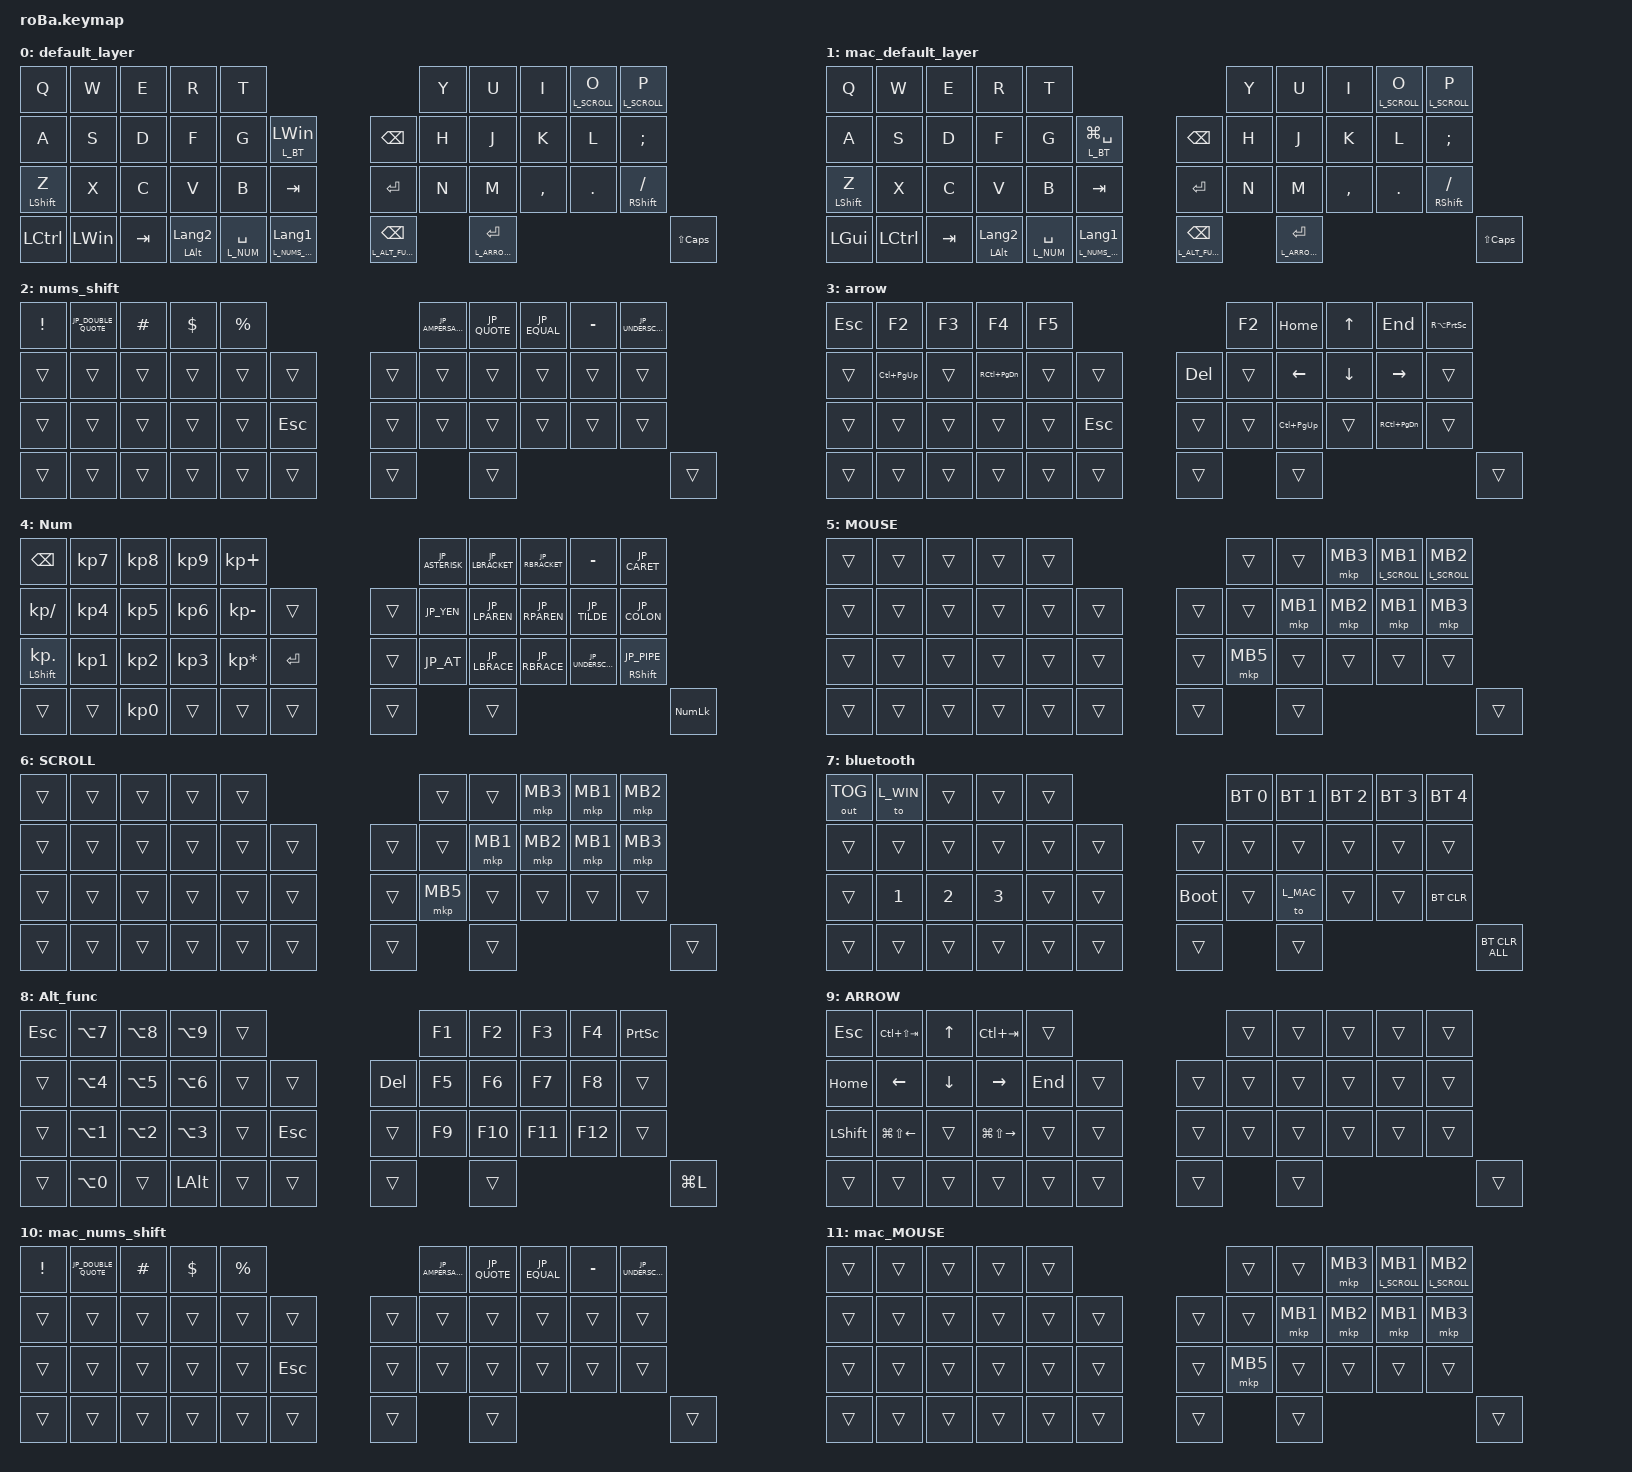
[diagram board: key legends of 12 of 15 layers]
#include <behaviors.dtsi>
#include <dt-bindings/zmk/bt.h>
#include <dt-bindings/zmk/keys.h>
#include <dt-bindings/zmk/outputs.h>
#include <dt-bindings/zmk/pointing.h>

// #include "keys_jp.h"

#define ZMK_POINTING_DEFAULT_SCRL_VAL 80

// #define AML 4  // Your AML layer index / AMLレイヤーのインデックス

// Layer indices / レイヤー番号
// mac_default_layer は共有レイヤー(arrow, Num, bluetooth)より下に置く必要がある
// MAC 版レイヤー(L_MAC_*)は conditional_layers で「MAC + 元レイヤー」のとき自動で有効になる
#define L_WIN             0
#define L_MAC             1
#define L_NUMS_SHIFT      2
#define L_ARROW_FN        3
#define L_NUM             4
#define L_MOUSE           5   // AML: roBa_R.overlay の AML と揃えること
#define L_SCROLL          6
#define L_BT              7
#define L_ALT_FUNC        8
#define L_ARROW           9
#define L_MAC_NUMS_SHIFT 10
#define L_MAC_MOUSE      11
#define L_MAC_SCROLL     12
#define L_MAC_ALT_FUNC   13
#define L_MAC_ARROW      14

#define JP_QUOTE        AMPERSAND         // '  (LS(N7) → JP Shift+7 = ')
#define JP_DOUBLE_QUOTE AT_SIGN           // "  (LS(N2) → JP Shift+2 = ")
#define JP_AMPERSAND    CARET             // &  (LS(N6) → JP Shift+6 = &)
#define JP_EQUAL        UNDERSCORE        // =  (LS(MINUS) → JP Shift+- = =)
#define JP_CARET        EQUAL             // ^
#define JP_YEN          INT3              // ¥  (HID 0x89)
#define JP_PLUS         COLON             // +  (LS(SEMICOLON) → JP Shift+; = +)
#define JP_TILDE        PLUS              // ~  (LS(EQUAL) → JP Shift+^ = ~)
#define JP_PIPE         LS(INT3)          // |  (LS(0x89))
#define JP_AT           LEFT_BRACKET      // @
#define JP_COLON        SINGLE_QUOTE      // :
#define JP_ASTERISK     DOUBLE_QUOTES     // *  (LS(SINGLE_QUOTE) → JP Shift+: = *)
#define JP_BACKQUOTE    LEFT_BRACE        // `  (LS(LEFT_BRACKET) → JP Shift+@ = `)
#define JP_UNDERSCORE   LS(INT1)          // _  (LS(0x87))
#define JP_LBRACKET     RIGHT_BRACKET     // [
#define JP_RBRACKET     BACKSLASH         // ]
#define JP_LPAREN       ASTERISK          // (  (LS(N8) → JP Shift+8 = ()
#define JP_RPAREN       LEFT_PARENTHESIS  // )  (LS(N9) → JP Shift+9 = ))
#define JP_LBRACE       RIGHT_BRACE       // {  (LS(RIGHT_BRACKET) → JP Shift+[ = {)
#define JP_RBRACE       PIPE              // }  (LS(BACKSLASH) → JP Shift+] = })
#define JP_KANA         LANGUAGE_1        // かな
#define JP_EISU         LANGUAGE_2        // 英数
#define JP_HANZEN       GRAVE             // 半角/全角

&mt {
    flavor = "balanced";
    quick-tap-ms = <0>;
};

&trackball {
    scroll-layers = <L_SCROLL>;

    // arrows {
    //     layers = <3>;
    //     bindings =
    //         <&kp RIGHT_ARROW>,
    //         <&kp LEFT_ARROW>,
    //         <&kp UP_ARROW>,
    //         <&kp DOWN_ARROW>;
    //     tick = <10>;
    //     wait-ms = <5>;
    //     tap-ms = <5>;
    // };
};

/ {
    zip_temp_layer_threshold: zip_temp_layer_threshold {
        compatible = "zmk,input-processor-temp-layer-threshold";
        #input-processor-cells = <2>;
        
        // Cumulative movement required before activation
        // AML発動に必要な累積移動量（大きくするほど誤作動しにくい）
        threshold = <25>;

        // Key positions that won't deactivate the layer
        // 以下で指定したキー以外を押すとAML解除
        excluded-positions = <7 8 9 17 18 19 20 21 22 34> ;

        // Don't activate if key was pressed within this time
        // キー入力から300ms間はAMLを発動しない
        require-prior-idle-ms = <300>;

        // Reset accumulated movement after this timeout
        // 蓄積された移動量をリセットするまでの時間（短くするとドリフト蓄積を防ぐ）
        reset-timeout-ms = <100>;
    };


    combos { compatible = "zmk,combos"; };

    macros {
        to_layer_0: to_layer_0 {
            compatible = "zmk,behavior-macro-one-param";
            #binding-cells = <1>;
            bindings = <&to 0 &macro_param_1to1 &kp MACRO_PLACEHOLDER>;
            label = "TO_LAYER_0";
        };

        to_layer_mac: to_layer_mac {
            compatible = "zmk,behavior-macro-one-param";
            #binding-cells = <1>;
            bindings = <&to L_MAC &macro_param_1to1 &kp MACRO_PLACEHOLDER>;
            label = "TO_LAYER_MAC";
        };
    };

    conditional_layers {
        compatible = "zmk,conditional-layers";

        mac_nums_shift {
            if-layers = <L_MAC L_NUMS_SHIFT>;
            then-layer = <L_MAC_NUMS_SHIFT>;
        };

        mac_mouse {
            if-layers = <L_MAC L_MOUSE>;
            then-layer = <L_MAC_MOUSE>;
        };

        mac_scroll {
            if-layers = <L_MAC L_SCROLL>;
            then-layer = <L_MAC_SCROLL>;
        };

        mac_alt_func {
            if-layers = <L_MAC L_ALT_FUNC>;
            then-layer = <L_MAC_ALT_FUNC>;
        };

        mac_arrow {
            if-layers = <L_MAC L_ARROW>;
            then-layer = <L_MAC_ARROW>;
        };
    };

    behaviors {
        lt_to_layer_0: lt_to_layer_0 {
            compatible = "zmk,behavior-hold-tap";
            label = "LAYER_TAP_TO_0";
            bindings = <&mo>, <&to_layer_0>;

            #binding-cells = <2>;
            tapping-term-ms = <200>;
        };

        lt_to_layer_mac: lt_to_layer_mac {
            compatible = "zmk,behavior-hold-tap";
            label = "LAYER_TAP_TO_MAC";
            bindings = <&mo>, <&to_layer_mac>;

            #binding-cells = <2>;
            tapping-term-ms = <200>;
        };

        lt_to_layer_0_delay: lt_to_layer_0_delay {
            compatible = "zmk,behavior-hold-tap";
            label = "LAYER_TAP_TO_0_delay";
            bindings = <&mo>, <&to_layer_0>;
            flavor = "balanced";

            #binding-cells = <2>;
            tapping-term-ms = <900>;
            quick-tap-ms = <900>;
            require-prior-idle-ms = <120>;
            hold-trigger-key-positions = <>;
        };

        lt_kp_delay: lt_kp_delay {
            compatible = "zmk,behavior-hold-tap";
            label = "LAYER_TAP_KP_DELAY";
            bindings = <&mo>, <&kp>;
            flavor = "balanced";

            #binding-cells = <2>;
            tapping-term-ms = <900>;
            quick-tap-ms = <900>;
            require-prior-idle-ms = <120>;
            hold-trigger-key-positions = <>;
        };

        mo_mb1_delay: mo_mb1_delay {
            compatible = "zmk,behavior-hold-tap";
            label = "MO_MB1_DELAY";
            #binding-cells = <2>;
            tapping-term-ms = <500>;
            flavor = "tap-preferred";
            bindings = <&mo>, <&mkp>;
        };

        mo_mb1: mo_mb1 {
            compatible = "zmk,behavior-hold-tap";
            label = "MO_MB1";
            #binding-cells = <2>;
            tapping-term-ms = <200>;
            flavor = "balanced";
            bindings = <&mo>, <&mkp>;
        };

        encoder_msc_down_up: encoder_msc_down_up {
            compatible = "zmk,behavior-sensor-rotate";
            label = "ENCODER_MSC_DOWN_UP";
            #sensor-binding-cells = <0>;
            bindings = <&msc SCRL_DOWN>, <&msc SCRL_UP>;

            tap-ms = <20>;
        };
    };

    keymap {
        compatible = "zmk,keymap";

        default_layer {
            bindings = <
&kp Q             &kp W         &kp E    &kp R                    &kp T                                                                                                        &kp Y  &kp U  &kp I      &lt_kp_delay L_SCROLL O  &lt_kp_delay L_SCROLL P
&kp A             &kp S         &kp D    &kp F                    &kp G                               &lt_to_layer_0 L_BT LEFT_WIN               &kp BACKSPACE                     &kp H  &kp J  &kp K      &kp L                    &kp SEMICOLON
&mt LEFT_SHIFT Z  &kp X         &kp C    &kp V                    &kp B                               &kp TAB                                    &kp ENTER                         &kp N  &kp M  &kp COMMA  &kp DOT                  &mt RIGHT_SHIFT SLASH
&kp LCTRL         &kp LEFT_WIN  &kp TAB  &mt LEFT_ALT LANGUAGE_2  &lt_to_layer_0 L_NUM SPACE          &lt_to_layer_0 L_NUMS_SHIFT LANGUAGE_1     &lt_to_layer_0 L_ALT_FUNC BACKSPACE    &lt_to_layer_0 L_ARROW_FN ENTER                                       &kp LS(CAPS)
            >;

            sensor-bindings = <&encoder_msc_down_up>;
        };

        // Mac 用ベース: Ctrl 位置に Cmd、Win 位置に Ctrl、Win キータップ → Cmd+Space (Spotlight)
        // 親指キーのタップ時は &to L_MAC で Mac モードに戻る
        mac_default_layer {
            bindings = <
&kp Q             &kp W         &kp E    &kp R                    &kp T                                                                                                        &kp Y  &kp U  &kp I      &lt_kp_delay L_SCROLL O  &lt_kp_delay L_SCROLL P
&kp A             &kp S         &kp D    &kp F                    &kp G                               &lt_to_layer_mac L_BT LG(SPACE)            &kp BACKSPACE                     &kp H  &kp J  &kp K      &kp L                    &kp SEMICOLON
&mt LEFT_SHIFT Z  &kp X         &kp C    &kp V                    &kp B                               &kp TAB                                    &kp ENTER                         &kp N  &kp M  &kp COMMA  &kp DOT                  &mt RIGHT_SHIFT SLASH
&kp LEFT_GUI      &kp LCTRL     &kp TAB  &mt LEFT_ALT LANGUAGE_2  &lt_to_layer_mac L_NUM SPACE        &lt_to_layer_mac L_NUMS_SHIFT LANGUAGE_1   &lt_to_layer_mac L_ALT_FUNC BACKSPACE  &lt_to_layer_mac L_ARROW_FN ENTER                                     &kp LS(CAPS)
            >;

            sensor-bindings = <&encoder_msc_down_up>;
        };

        nums_shift {
            bindings = <
&kp EXCLAMATION  &kp JP_DOUBLE_QUOTE  &kp HASH  &kp DOLLAR  &kp PERCENT                         &kp JP_AMPERSAND  &kp JP_QUOTE  &kp JP_EQUAL  &kp MINUS  &kp JP_UNDERSCORE
&trans           &trans               &trans    &trans      &trans       &trans      &trans      &trans            &trans        &trans        &trans     &trans
&trans           &trans               &trans    &trans      &trans       &kp ESCAPE  &trans      &trans            &trans        &trans        &trans     &trans
&trans           &trans               &trans    &trans      &trans       &trans      &trans      &trans                                                   &trans
            >;
        };

        arrow {
            bindings = <
&kp ESCAPE  &kp F2            &kp F3    &kp F4              &kp F5                              &kp F2  &kp HOME         &kp UP    &kp END            &kp RA(PRINTSCREEN)
&trans      &kp LC(PAGE_UP)   &trans    &kp RC(PAGE_DOWN)   &trans   &trans      &kp DELETE      &trans  &kp LEFT         &kp DOWN  &kp RIGHT          &trans
&trans      &trans            &trans    &trans              &trans   &kp ESCAPE  &trans          &trans  &kp LC(PAGE_UP)  &trans    &kp RC(PAGE_DOWN)  &trans
&trans      &trans            &trans    &trans              &trans   &trans      &trans          &trans                                                &trans
            >;

            sensor-bindings = <&inc_dec_kp PAGE_UP PAGE_DOWN>;
        };

        Num {
            bindings = <
&kp BSPC                &kp KP_N7      &kp KP_N8  &kp KP_N9  &kp KP_PLUS                                   &kp JP_ASTERISK  &kp JP_LBRACKET  &kp JP_RBRACKET  &kp MINUS          &kp JP_CARET
&kp KP_DIVIDE           &kp KP_N4      &kp KP_N5  &kp KP_N6  &kp KP_MINUS        &trans      &trans           &kp JP_YEN       &kp JP_LPAREN    &kp JP_RPAREN    &kp JP_TILDE       &kp JP_COLON
&mt LEFT_SHIFT KP_DOT   &kp KP_N1      &kp KP_N2  &kp KP_N3  &kp KP_ASTERISK  &kp RET     &trans           &kp JP_AT        &kp JP_LBRACE    &kp JP_RBRACE    &kp JP_UNDERSCORE  &mt RIGHT_SHIFT JP_PIPE
&trans                  &trans      &kp KP_N0  &trans  &trans           &trans      &trans           &trans                                                                &kp KP_NUMLOCK
            >;
        };

        MOUSE {
            bindings = <
&trans  &trans  &trans  &trans  &trans                      &trans    &trans    &mkp MB3  &mo_mb1 L_SCROLL MB1  &mo_mb1 L_SCROLL MB2
&trans  &trans  &trans  &trans  &trans  &trans      &trans  &trans    &mkp MB1  &mkp MB2  &mkp MB1              &mkp MB3
&trans  &trans  &trans  &trans  &trans  &trans      &trans  &mkp MB5  &trans    &trans    &trans                &trans
&trans  &trans  &trans  &trans  &trans  &trans      &trans  &trans                                              &trans
            >;

            sensor-bindings = <&encoder_msc_down_up>;
        };

        SCROLL {
            bindings = <
&trans  &trans  &trans  &trans  &trans                      &trans    &trans    &mkp MB3  &mkp MB1  &mkp MB2
&trans  &trans  &trans  &trans  &trans  &trans      &trans  &trans    &mkp MB1  &mkp MB2  &mkp MB1  &mkp MB3
&trans  &trans  &trans  &trans  &trans  &trans      &trans  &mkp MB5  &trans    &trans    &trans    &trans
&trans  &trans  &trans  &trans  &trans  &trans      &trans  &trans                                  &trans
            >;

            sensor-bindings = <&encoder_msc_down_up>;
        };

        // W 位置: Windows モード / M 位置: Mac モード
        bluetooth {
            bindings = <
&out OUT_TOG  &to L_WIN     &trans        &trans        &trans                           &bt BT_SEL 0  &bt BT_SEL 1  &bt BT_SEL 2  &bt BT_SEL 3  &bt BT_SEL 4
&trans        &trans        &trans        &trans        &trans  &trans      &trans       &trans        &trans        &trans        &trans        &trans
&trans        &kp NUMBER_1  &kp NUMBER_2  &kp NUMBER_3  &trans  &trans      &bootloader  &trans        &to L_MAC     &trans        &trans        &bt BT_CLR
&trans        &trans        &trans        &trans        &trans  &trans      &trans       &trans                                                  &bt BT_CLR_ALL
            >;
        };

        Alt_func {
            bindings = <
&kp ESCAPE  &kp LA(N7)  &kp LA(N8)  &kp LA(N9)    &trans                              &kp F1  &kp F2   &kp F3   &kp F4   &kp PRINTSCREEN
&trans      &kp LA(N4)  &kp LA(N5)  &kp LA(N6)    &trans  &trans      &kp DELETE      &kp F5  &kp F6   &kp F7   &kp F8   &trans
&trans      &kp LA(N1)  &kp LA(N2)  &kp LA(N3)    &trans  &kp ESCAPE  &trans          &kp F9  &kp F10  &kp F11  &kp F12  &trans
&trans      &kp LA(N0)  &trans      &kp LEFT_ALT  &trans  &trans      &trans          &trans                              &kp LG(L)
            >;
        };

        ARROW {
            bindings = <
&kp ESCAPE      &kp LC(LS(TAB))         &kp UP_ARROW    &kp LC(TAB)              &trans                       &trans  &trans  &trans  &trans  &trans
&kp HOME        &kp LEFT_ARROW          &kp DOWN_ARROW  &kp RIGHT_ARROW          &kp END  &trans      &trans   &trans  &trans  &trans  &trans  &trans
&kp LEFT_SHIFT  &kp LG(LS(LEFT_ARROW))  &trans          &kp LG(LS(RIGHT_ARROW))  &trans   &trans      &trans   &trans  &trans  &trans  &trans  &trans
&trans          &trans                  &trans          &trans                   &trans   &trans      &trans   &trans                          &trans
            >;

            sensor-bindings = <&inc_dec_kp LC(PAGE_UP) LC(PAGE_DOWN)>;
        };

        // ---- 以下 Mac 版 (conditional_layers により L_MAC + 元レイヤーで自動的に有効) ----

        mac_nums_shift {
            bindings = <
&kp EXCLAMATION  &kp JP_DOUBLE_QUOTE  &kp HASH  &kp DOLLAR  &kp PERCENT                         &kp JP_AMPERSAND  &kp JP_QUOTE  &kp JP_EQUAL  &kp MINUS  &kp JP_UNDERSCORE
&trans           &trans               &trans    &trans      &trans       &trans      &trans      &trans            &trans        &trans        &trans     &trans
&trans           &trans               &trans    &trans      &trans       &kp ESCAPE  &trans      &trans            &trans        &trans        &trans     &trans
&trans           &trans               &trans    &trans      &trans       &trans      &trans      &trans                                                   &trans
            >;
        };

        mac_MOUSE {
            bindings = <
&trans  &trans  &trans  &trans  &trans                      &trans    &trans    &mkp MB3  &mo_mb1 L_SCROLL MB1  &mo_mb1 L_SCROLL MB2
&trans  &trans  &trans  &trans  &trans  &trans      &trans  &trans    &mkp MB1  &mkp MB2  &mkp MB1              &mkp MB3
&trans  &trans  &trans  &trans  &trans  &trans      &trans  &mkp MB5  &trans    &trans    &trans                &trans
&trans  &trans  &trans  &trans  &trans  &trans      &trans  &trans                                              &trans
            >;

            sensor-bindings = <&encoder_msc_down_up>;
        };

        mac_SCROLL {
            bindings = <
&trans  &trans  &trans  &trans  &trans                      &trans    &trans    &mkp MB3  &mkp MB1  &mkp MB2
&trans  &trans  &trans  &trans  &trans  &trans      &trans  &trans    &mkp MB1  &mkp MB2  &mkp MB1  &mkp MB3
&trans  &trans  &trans  &trans  &trans  &trans      &trans  &mkp MB5  &trans    &trans    &trans    &trans
&trans  &trans  &trans  &trans  &trans  &trans      &trans  &trans                                  &trans
            >;

            sensor-bindings = <&encoder_msc_down_up>;
        };

        // Alt+数字 → Cmd+数字 / PrintScreen → Cmd+Shift+5 / Win+L → Ctrl+Cmd+Q (画面ロック)
        mac_Alt_func {
            bindings = <
&kp ESCAPE  &kp LG(N7)  &kp LG(N8)  &kp LG(N9)    &trans                              &kp F1  &kp F2   &kp F3   &kp F4   &kp LG(LS(N5))
&trans      &kp LG(N4)  &kp LG(N5)  &kp LG(N6)    &trans  &trans      &kp DELETE      &kp F5  &kp F6   &kp F7   &kp F8   &trans
&trans      &kp LG(N1)  &kp LG(N2)  &kp LG(N3)    &trans  &kp ESCAPE  &trans          &kp F9  &kp F10  &kp F11  &kp F12  &trans
&trans      &kp LG(N0)  &trans      &kp LEFT_ALT  &trans  &trans      &trans          &trans                              &kp LC(LG(Q))
            >;
        };

        // Home/End → Cmd+←/→ (行頭/行末)
        // Win+Shift+←/→ (ウィンドウを別ディスプレイへ) → Ctrl+Opt+Cmd+←/→ (Rectangle の前/次ディスプレイ)
        mac_ARROW {
            bindings = <
&kp ESCAPE      &kp LC(LS(TAB))             &kp UP_ARROW    &kp LC(TAB)                  &trans                             &trans  &trans  &trans  &trans  &trans
&kp LG(LEFT)    &kp LEFT_ARROW              &kp DOWN_ARROW  &kp RIGHT_ARROW              &kp LG(RIGHT)  &trans      &trans   &trans  &trans  &trans  &trans  &trans
&kp LEFT_SHIFT  &kp LC(LA(LG(LEFT_ARROW)))  &trans          &kp LC(LA(LG(RIGHT_ARROW)))  &trans         &trans      &trans   &trans  &trans  &trans  &trans  &trans
&trans          &trans                      &trans          &trans                       &trans         &trans      &trans   &trans                          &trans
            >;

            sensor-bindings = <&inc_dec_kp LC(LS(TAB)) LC(TAB)>;
        };
    };
};
